# wsoc_ocla_secure register map
Vendor: Texas Instruments
Peripheral module from a debugger description file (folder CC35X1).
Registers are 32-bit, read-write, reset 0x0 unless marked. A register's access mark holds for its fields unless they carry their own. Offsets are as the file gives them; lines under a group give offsets from that group; [hi:lo] are bit positions; {n}, {i} and the like mark numbered series; 'fields as' and 'values as' point back to an identical list; <NAME> marks a mode.

## wsoc_ocla_secure
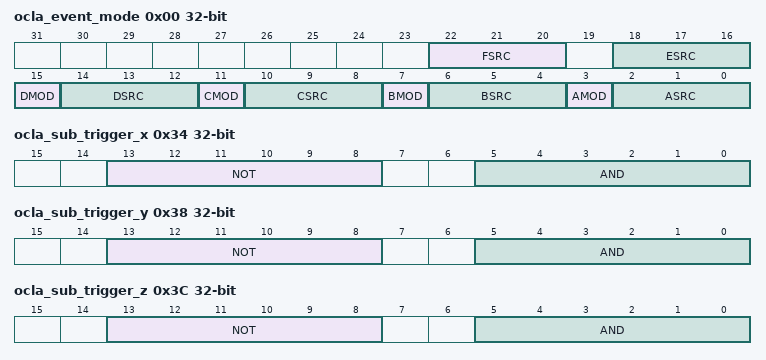
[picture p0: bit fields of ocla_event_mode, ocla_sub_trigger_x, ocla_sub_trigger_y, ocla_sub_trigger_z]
0x00 ocla_event_mode access per field — Events Mode and Source.
  [22:20] FSRC rw — Which part of the monitor bus enter event F: 0x0. event_f_input = mon_in_en[31:0]; 0x1. event_f_input = mon_in_en[47:16]; 0x2. event_f_input = mon_in_en[63:32]; 0x3. event_f_input = mon_in_en[79:48]; 0x4. event_f_input = mon_in_en[95:64]; 0x5. event_f_input = {mon_in_en[95:80], mon_in_en[15:0]};
  [18:16] ESRC rw — Which part of the monitor bus enter event E: 0x0. event_e_input = mon_in_en[31:0]; 0x1. event_e_input = mon_in_en[47:16]; 0x2. event_e_input = mon_in_en[63:32]; 0x3. event_e_input = mon_in_en[79:48]; 0x4. event_e_input = mon_in_en[95:64]; 0x5. event_e_input = {mon_in_en[95:80], mon_in_en[15:0]};
  [15] DMOD rw — Event D mode: 0. Equal 1. Great then
  [14:12] DSRC rw — Which part of the monitor bus enter event D: 0x0. event_d_input = mon_in_en[31:0]; 0x1. event_d_input = mon_in_en[47:16]; 0x2. event_d_input = mon_in_en[63:32]; 0x3. event_d_input = mon_in_en[79:48]; 0x4. event_d_input = mon_in_en[95:64]; 0x5. event_d_input = {mon_in_en[95:80], mon_in_en[15:0]};
  [11] CMOD rw — Event C mode: 0. Equal 1. Great then
  [10:8] CSRC rw — Which part of the monitor bus enter event C: 0x0. event_c_input = mon_in_en[31:0]; 0x1. event_c_input = mon_in_en[47:16]; 0x2. event_c_input = mon_in_en[63:32]; 0x3. event_c_input = mon_in_en[79:48]; 0x4. event_c_input = mon_in_en[95:64]; 0x5. event_c_input = {mon_in_en[95:80], mon_in_en[15:0]};
  [7] BMOD rw — Event B mode: 0. Equal 1. Great then
  [6:4] BSRC rw — Which part of the monitor bus enter event B: 0x0. event_b_input = mon_in_en[31:0]; 0x1. event_b_input = mon_in_en[47:16]; 0x2. event_b_input = mon_in_en[63:32]; 0x3. event_b_input = mon_in_en[79:48]; 0x4. event_b_input = mon_in_en[95:64]; 0x5. event_b_input = {mon_in_en[95:80], mon_in_en[15:0]};
  [3] AMOD rw — Event A mode: 0. Equal 1. Great then
  [2:0] ASRC rw — Which part of the monitor bus enter event A: 0x0. event_a_input = mon_in_en[31:0]; 0x1. event_a_input = mon_in_en[47:16]; 0x2. event_a_input = mon_in_en[63:32]; 0x3. event_a_input = mon_in_en[79:48]; 0x4. event_a_input = mon_in_en[95:64]; 0x5. event_a_input = {mon_in_en[95:80], mon_in_en[15:0]};
0x04 ocla_event_a_mask
  [31:0] MASK — mask bit which set to 0 is mask
0x08 ocla_event_a_comp — OCLA Event A Compare.
  [31:0] COMP — Compare value for event A
0x0C ocla_event_b_mask
  [31:0] MASK — mask bit which set to 0 is mask
0x10 ocla_event_b_comp — OCLA Event B Compare.
  [31:0] COMP — Compare value for event B
0x14 ocla_event_c_mask
  [31:0] MASK — mask bit which set to 0 is mask
0x18 ocla_event_c_comp — OCLA Event C Compare.
  [31:0] COMP — Compare value for event C
0x2C ocla_event_f_mask
  [31:0] MASK — mask bit which set to 0 is mask
0x30 ocla_event_f_comp — OCLA Event F Compare.
  [31:0] COMP — Compare value for event F
0x34 ocla_sub_trigger_x access per field — make sub trigger from the events (A,B,C,D,E,F) And and not on the events which will case for example: A & B & ~C. For this configure the AND to 6'h7 (C,B,A) and the not to 6'h4 (C) The order of the events are {F,E,D,C,B,A}.
  [13:8] NOT rw — Which event will have not
  [5:0] AND rw — Which event will be in the and
0x38 ocla_sub_trigger_y access per field — make sub trigger from the events (A,B,C,D,E,F) And and not on the events which will case for example: A & B & ~C. For this configure the AND to 6'h7 (C,B,A) and the not to 6'h4 (C) The order of the events are {F,E,D,C,B,A}.
  fields as ocla_sub_trigger_x
0x3C ocla_sub_trigger_z access per field — make sub trigger from the events (A,B,C,D,E,F) And and not on the events which will case for example: A & B & ~C. For this configure the AND to 6'h7 (C,B,A) and the not to 6'h4 (C) The order of the events are {F,E,D,C,B,A}.
  fields as ocla_sub_trigger_x
0x40 ocla_clk_cfg access per field — OCLA Clk Configuration.
  [1:0] MOD rw — Clock Mode: 0. No CLK 1. CLK40 2. RF CLK 3. Illegal NOTE: move between CLK should be through zero (No CLK)
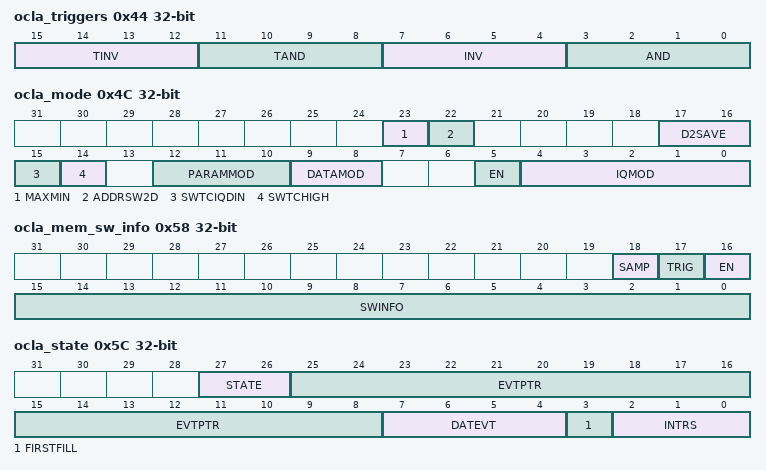
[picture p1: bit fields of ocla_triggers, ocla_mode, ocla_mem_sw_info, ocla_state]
0x44 ocla_triggers access per field — Triggers. configure the two triggers
  [15:12] TINV rw — which of the sub triggers will be invert for trigger1. The sub_triggers order is {W,Z,Y,X} to make ~X & Y use 4'h1
  [11:8] TAND rw — Which of the sub triggers will make the trigger2 The sub_triggers order is {W,Z,Y,X} to make ~X & Y use 4'h3.
  [7:4] INV rw — Which of the sub triggers will be invert for trigger1. The sub_triggers order is {W,Z,Y,X} to make ~X & Y use 4'h1
  [3:0] AND rw — Which of the sub triggers will make the trigger1 The sub_triggers order is {W,Z,Y,X} to make ~X & Y use 4'h3.
0x48 ocla_time access per field
  [25:0] TIME rw — use for: 1. For time between events for mode which check time between two events. 2. Number of event for modes that check number of event.
0x4C ocla_mode access per field reset not defined — main mode configurations, memory params, and output params.
  [23] MAXMIN rw — For max_time function can change it to min time by: max = 0, min = 1.
  [22] ADDRSW2D rw — Save the mem_sw on the bits [31:24]
  [17:16] D2SAVE rw — This do shift down to the monitor which saved (not the triggers) 0: monitor as it is. 1: Shift right 16 bits for mode of 32 bits monitor[47:16] for mode of 16 bits monitor[31:16] for mode of 8 bits monitor[24:16]. 2: Shift right 32 bits for mode of 32 bits monitor[63:32] for mode of 16 bits monitor[47:32] for mode of 8 bits monitor[39:32]. 3: Shift right 64 bits Don't use in 64bits mode for mode of 32 bits monitor[95:64] for mode of 16 bits monitor[79:64] for mode of 8 bits monitor[71:64]. for IQ save mode 14 0 : output is iq_save_in[63:0] 1: output is iq_save_in[127:64] 2: output is iq_save_in[127:0]
  [15] SWTCIQDIN rw — Switch between IQ_SAVE data in and debug bus in. This enable to do all triggers and save data on iq_in.
  [14] SWTCHIGH rw — At mode which switch iq with din (bit 15) take bits from 127 to 32 when this bit is one otherwise take 97:0.
  [12:10] PARAMMOD rw — not in use.
  [9:8] DATAMOD rw — // 0: save 64bits each cycle // 1: save 32bits each cycle (write to memory every two cycles) // 2: save 16LSB each cycle (write to the ram every 4 cycles) // 3: save 8LSB each cycle (write to the ram every 8 cycles) // for IQ save/inject modes // look at mode description.
  [5] EN rw — Enable the OCLA should be the last write
  [4:0] IQMOD rw — // 0: event1 happened // 1: check time between last event_a to first event_b if it's bigger then mem_time event // 2: check time between last event_a high to first event_b high if it's smaller then mem_time event // 3: check the time from first event a to first event b if it's bigger then mem_time event // 4: check the time from first event a to first event b if it's smaller then mem_time event // 5: event1 happened T times // 6: timestamp mode save events and timestamp // 7: event1 happened but event2 didn't happened for T cycles // 8: trigger A happened and next cycle trigger B happened sample monitor after timestamp once (as timestamp mode) // 9: SW event when the mem_sw_info == 16'hffff // 10: Save monitor bus and time stamp when monitor change masking from F trigger // 11: Save T amount of samples when event1 happened // 12: Save each time one of the trigger (A-F) happened // 13: IQ Save 64 bit every cycle - 32LSB monitor bus, // 32 MSB bits are 32 LSB from IQ bus // 14: IQ save // 32/64/128 bits IQ save mode // If (mem_data_save_mode = 0) // case (mem_data_to_save) // 0: ocla_dout[63:0] <= #1 ocla_iq_save_in[63:0]; // 1: ocla_dout[63:0] <= #1 ocla_iq_save_in[127:64]; // 2: ocla_dout[127:0] <= #1 ocla_iq_save_in[127:0]; // save each cycle // If (mem_data_save_mode = 1) // case (mem_data_to_save) // 0: ocla_dout[31:0] <= #1 ocla_iq_save_in[31:0]; // 1: ocla_dout[31:0] <= #1 ocla_iq_save_in[63:32]; // 2: ocla_dout[31:0] <= #1 ocla_iq_save_in[95:64]; // 3: ocla_dout[31:0] <= #1 ocla_iq_save_in[127:96]; // 15: IQ inject // 16: ocla debug write to the RAM {14'h3333, ocla_addr[17:0], 14'h2222, ocla_addr[17:0], 14'h1111, ocla_addr[17:0], 14'h0000, ocla_addr[17:0]}
0x50 ocla_mem_mem_size access per field — OCLA Memory Size.
  [7:0] SIZE rw — The last address in the memory OCLA use. this is the 8 MSB out of 18 bits of 128bit wide lines. (concatenated with 0x3FF to form the last address).
0x54 ocla_mem_mem_size_after_event access per field — Memory Size After Event.
  [17:0] SIZE rw — Number of writes (128bit wide each) to the memory after the event
0x58 ocla_mem_sw_info access per field — Memory SW Info. Register which write to the memory as part of the data for SW HW alignment. can also trigger an event to start OCLA recording.
  [18] SAMP rw — signal to force re-sampling of the sw_info data into the recorded bus,
  [17] TRIG rw — raise bit to issue sw trigger.
  [16] EN rw — When this bit is one and at ocla mode of not 6, 10 save the data.
  [15:0] SWINFO rw — Data save in memory . not in mode : 6 , 10. At mode of 64bits save it as MSB when en is high.
0x5C ocla_state ro reset not defined — Hold the pointer to the place in memory which event happened
  [27:26] STATE — State machine: 0: looking for the event. 1: event found. 2: finish.
  [25:8] EVTPTR — the address of the memory when event happened.
  [7:4] DATEVT — This is as LSB of the event_ptr when use mode other then 64bits 0 event happened when the building of the 64bits was full. 1 event happened when the building of the 64 bits was on 8 bits. 2 event happened when the building of the 64 bits was on 16 bits. ...
  [3] FIRSTFILL — Indicates if this is the first time that the RAM is fill and therefore part of the RAM is unknown. This value should be read when OCLA is finished working, before disabling the OCLA, because it is reset when OCLA is disabled.
  [2:0] INTRS — To read the OCLA state ocla_mem_phase[1] - before or after the event event_t_reg, event_reg
0x60 ocla_read_debug0 ro — Read Debug 0. Read the debug bus enter to OCLA 32 LSB
  [31:0] _31TO0 — 32 LSBs
0x64 ocla_read_debug1 ro — Read Debug 1. Read the debug bus enter to OCLA 63-32
  [31:0] _63TO32 — 63 to 32 Bits.
0x6C ocla_read_max_time ro — Read Max Time.
  [25:0] MAXTIME — Value of the counter of max/min read
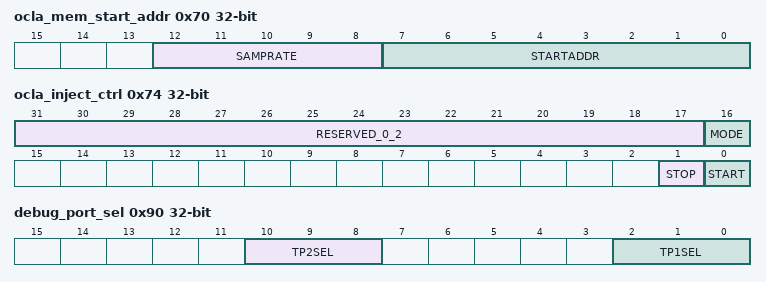
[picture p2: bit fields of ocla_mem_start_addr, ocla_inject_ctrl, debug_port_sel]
0x70 ocla_mem_start_addr access per field — Memory Start Address.
  [12:8] SAMPRATE rw — Sample to the RAM once each X times
  [7:0] STARTADDR rw — Which address the RAM start, change only for the 8 MSB, the 10 LSB is always 0.
0x74 ocla_inject_ctrl access per field — OCLA Inject Control.
  [31:17] RESERVED_0_2 ro — STOP INJECT
  [16] MODE rw — Inject Mode: 0. Single INJECT mode (Stop when Address=Max address) 1. Multi INJECT mode (stop when Wr to "stop" field)
  [1] STOP wo — Which address the RAM start, change only for the 8 MSB, the 10 LSB is always 0.
  [0] START wo — Start INJECT
{0x78+4i} debug_port_32_32_cfg_{i} reset not defined (i=0..4) — Debug Port CFG {i}.
  [31:0] BIT{i}SEL — Bit {i}.
0x8C debug_port_tp1_or_tp2 reset not defined
  [31:0] SEL — Each bit select which TP1 or TP2 would connect to OCLA bus bits[63:32] 0. select TP2 1. select TP1 Note: OCLA bus [31:0] is TP1
0x90 debug_port_sel access per field reset not defined — Debug Port Selector.
  [10:8] TP2SEL rw — Select which debug port used by OCLA for TP2 --> [63:32] 0x0. select PHY Debug Port 0x1. select WSOC Debug Port 0x2. select TOP Debug Port 0x3. select BLE Debug Port 0x4. select Peripheral Debug Port
  [2:0] TP1SEL rw — Select which debug port used by OCLA for TP1 --> [31:0] 0x0. select PHY Debug Port 0x1. select WSOC Debug Port 0x2. select TOP Debug Port 0x3. select BLE Debug Port 0x4. select Peripheral Debug Port
0x94 dbg_out_sel — Debug Out Selector. select if debug port output is connected to GPIO values (OCP mapped register) or to debug port.
  [31:0] SEL — per bit selection 0. GPIO 1. debug port
0x98 gpio_out_val — GPIO Out Value.
  [31:0] VAL — GPIO out read/write value.
0x9C gpio_out_val_set — GPIO Out Value Set.
  [31:0] SET — writing 1 to a bit will set the [OUTVAL.VAL]. writing 0 is ignored
0xA0 gpio_out_val_clr — GPIO Out Value Clear.
  [31:0] CLR — writing 1 to a bit will clr a bit [OUTVAL.VAL]
0xA4 gpio_out_val_toggle — GPIO Out Value Toggle.
  [31:0] TOGGLE — writing 1 to a bit will toggle a bit at [OUTVAL.VAL].
0xA8 gpio_out_val_pulse — GPIO Out Value Pulse.
  [31:0] PULSE — writing 1 to a bit will create a pulse for the same bit at [OUTVAL.VAL] ( Pulse is equal to toggle twice )
0xB0 ocla_tsf_on_trigger ro — TSF on Trigger. this is the 32 lower bits of the tsf latched on final trigger event
  [31:0] TIMESTAMP — TSF time stamp samled on trigger.
